# ipro6s register map
Vendor: intelpro; Series: IPRO6S
CPU: ipro6s, little endian
Registers are 32-bit, read-write, reset 0x0 unless marked. A register's access mark holds for its fields unless they carry their own. Offsets are from the block's base; [hi:lo] are bit positions; {n}, {i} and the like mark numbered series.

## MJENC_Q_SRAM
Base 0x3001A000
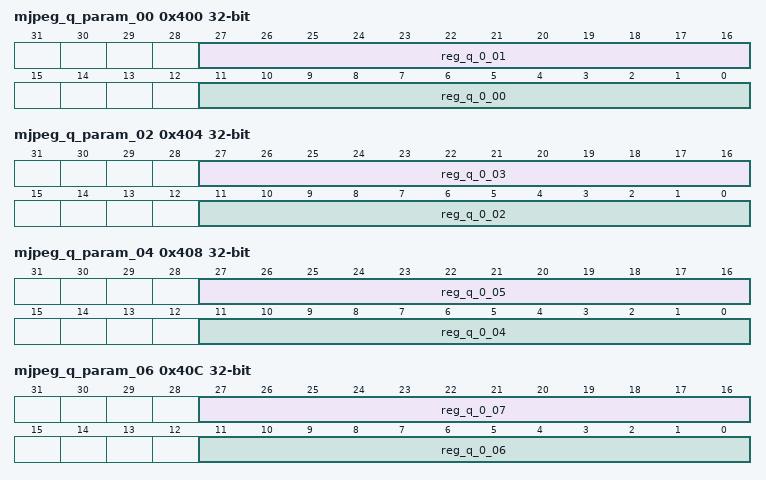
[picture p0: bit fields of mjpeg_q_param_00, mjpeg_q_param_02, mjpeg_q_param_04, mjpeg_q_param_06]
0x400 mjpeg_q_param_00
  [27:16] reg_q_0_01 — MJPEG Q parameter
  [11:0] reg_q_0_00 — MJPEG Q parameter
0x404 mjpeg_q_param_02
  [27:16] reg_q_0_03 — MJPEG Q parameter
  [11:0] reg_q_0_02 — MJPEG Q parameter
0x408 mjpeg_q_param_04
  [27:16] reg_q_0_05 — MJPEG Q parameter
  [11:0] reg_q_0_04 — MJPEG Q parameter
0x40C mjpeg_q_param_06
  [27:16] reg_q_0_07 — MJPEG Q parameter
  [11:0] reg_q_0_06 — MJPEG Q parameter
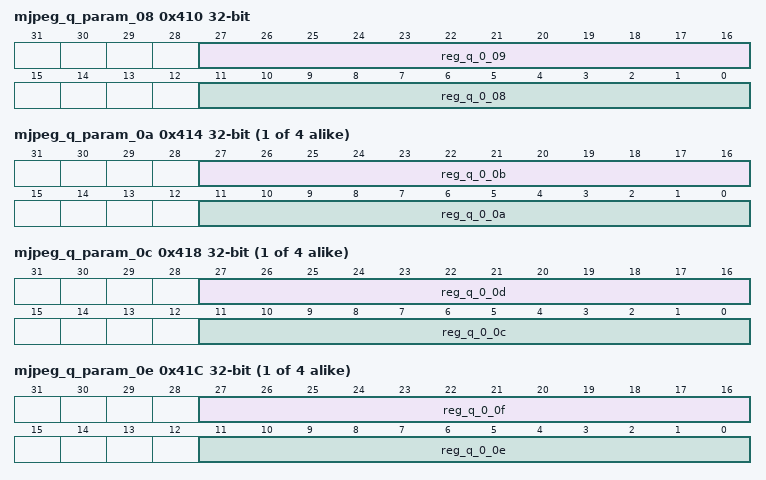
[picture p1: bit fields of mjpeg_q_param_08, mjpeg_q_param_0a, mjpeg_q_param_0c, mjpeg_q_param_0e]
0x410 mjpeg_q_param_08
  [27:16] reg_q_0_09 — MJPEG Q parameter
  [11:0] reg_q_0_08 — MJPEG Q parameter
{0x414+0x20*i} mjpeg_q_param_{i}a (i=0..3)
  [27:16] reg_q_0_{i}b — MJPEG Q parameter
  [11:0] reg_q_0_{i}a — MJPEG Q parameter
{0x418+0x20*i} mjpeg_q_param_{i}c (i=0..3)
  [27:16] reg_q_0_{i}d — MJPEG Q parameter
  [11:0] reg_q_0_{i}c — MJPEG Q parameter
{0x41C+0x20*i} mjpeg_q_param_{i}e (i=0..3)
  [27:16] reg_q_0_{i}f — MJPEG Q parameter
  [11:0] reg_q_0_{i}e — MJPEG Q parameter
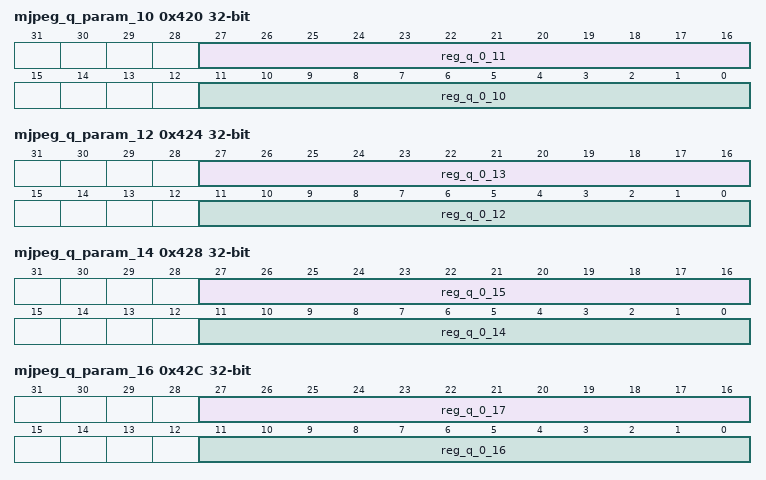
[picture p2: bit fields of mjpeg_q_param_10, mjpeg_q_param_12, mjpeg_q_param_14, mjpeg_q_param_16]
0x420 mjpeg_q_param_10
  [27:16] reg_q_0_11 — MJPEG Q parameter
  [11:0] reg_q_0_10 — MJPEG Q parameter
0x424 mjpeg_q_param_12
  [27:16] reg_q_0_13 — MJPEG Q parameter
  [11:0] reg_q_0_12 — MJPEG Q parameter
0x428 mjpeg_q_param_14
  [27:16] reg_q_0_15 — MJPEG Q parameter
  [11:0] reg_q_0_14 — MJPEG Q parameter
0x42C mjpeg_q_param_16
  [27:16] reg_q_0_17 — MJPEG Q parameter
  [11:0] reg_q_0_16 — MJPEG Q parameter
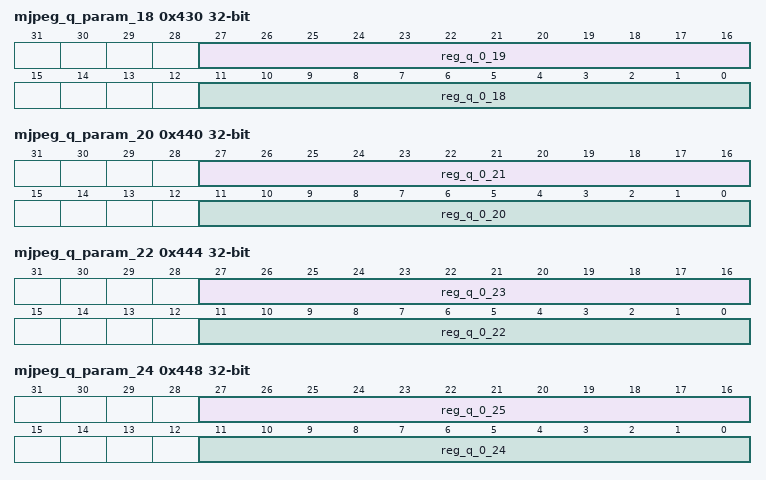
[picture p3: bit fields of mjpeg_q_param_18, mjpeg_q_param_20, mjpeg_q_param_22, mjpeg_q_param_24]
0x430 mjpeg_q_param_18
  [27:16] reg_q_0_19 — MJPEG Q parameter
  [11:0] reg_q_0_18 — MJPEG Q parameter
0x440 mjpeg_q_param_20
  [27:16] reg_q_0_21 — MJPEG Q parameter
  [11:0] reg_q_0_20 — MJPEG Q parameter
0x444 mjpeg_q_param_22
  [27:16] reg_q_0_23 — MJPEG Q parameter
  [11:0] reg_q_0_22 — MJPEG Q parameter
0x448 mjpeg_q_param_24
  [27:16] reg_q_0_25 — MJPEG Q parameter
  [11:0] reg_q_0_24 — MJPEG Q parameter
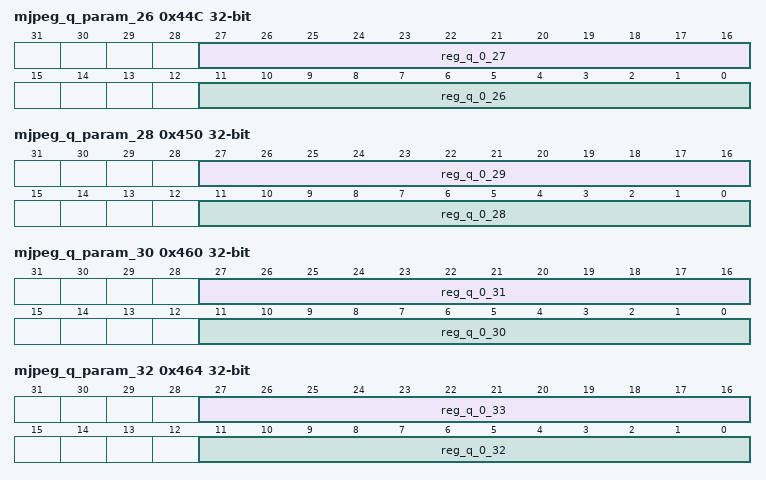
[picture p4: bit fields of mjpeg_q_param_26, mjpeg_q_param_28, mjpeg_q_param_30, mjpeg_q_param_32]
0x44C mjpeg_q_param_26
  [27:16] reg_q_0_27 — MJPEG Q parameter
  [11:0] reg_q_0_26 — MJPEG Q parameter
0x450 mjpeg_q_param_28
  [27:16] reg_q_0_29 — MJPEG Q parameter
  [11:0] reg_q_0_28 — MJPEG Q parameter
0x460 mjpeg_q_param_30
  [27:16] reg_q_0_31 — MJPEG Q parameter
  [11:0] reg_q_0_30 — MJPEG Q parameter
0x464 mjpeg_q_param_32
  [27:16] reg_q_0_33 — MJPEG Q parameter
  [11:0] reg_q_0_32 — MJPEG Q parameter
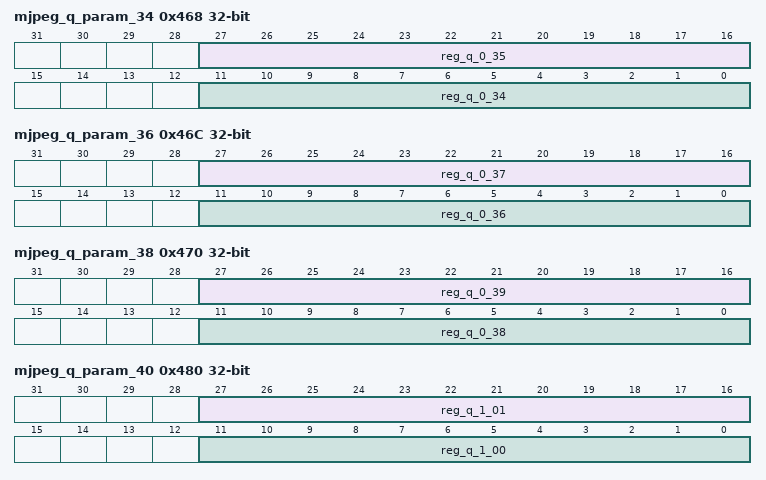
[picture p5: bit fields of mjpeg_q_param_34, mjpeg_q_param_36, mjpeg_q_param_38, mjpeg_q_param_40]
0x468 mjpeg_q_param_34
  [27:16] reg_q_0_35 — MJPEG Q parameter
  [11:0] reg_q_0_34 — MJPEG Q parameter
0x46C mjpeg_q_param_36
  [27:16] reg_q_0_37 — MJPEG Q parameter
  [11:0] reg_q_0_36 — MJPEG Q parameter
0x470 mjpeg_q_param_38
  [27:16] reg_q_0_39 — MJPEG Q parameter
  [11:0] reg_q_0_38 — MJPEG Q parameter
0x480 mjpeg_q_param_40
  [27:16] reg_q_1_01 — MJPEG Q parameter
  [11:0] reg_q_1_00 — MJPEG Q parameter
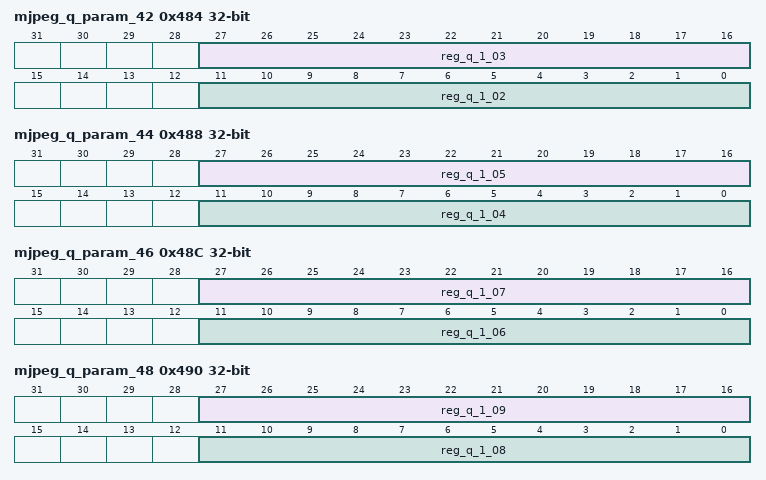
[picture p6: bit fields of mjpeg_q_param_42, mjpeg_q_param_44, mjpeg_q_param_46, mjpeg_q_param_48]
0x484 mjpeg_q_param_42
  [27:16] reg_q_1_03 — MJPEG Q parameter
  [11:0] reg_q_1_02 — MJPEG Q parameter
0x488 mjpeg_q_param_44
  [27:16] reg_q_1_05 — MJPEG Q parameter
  [11:0] reg_q_1_04 — MJPEG Q parameter
0x48C mjpeg_q_param_46
  [27:16] reg_q_1_07 — MJPEG Q parameter
  [11:0] reg_q_1_06 — MJPEG Q parameter
0x490 mjpeg_q_param_48
  [27:16] reg_q_1_09 — MJPEG Q parameter
  [11:0] reg_q_1_08 — MJPEG Q parameter
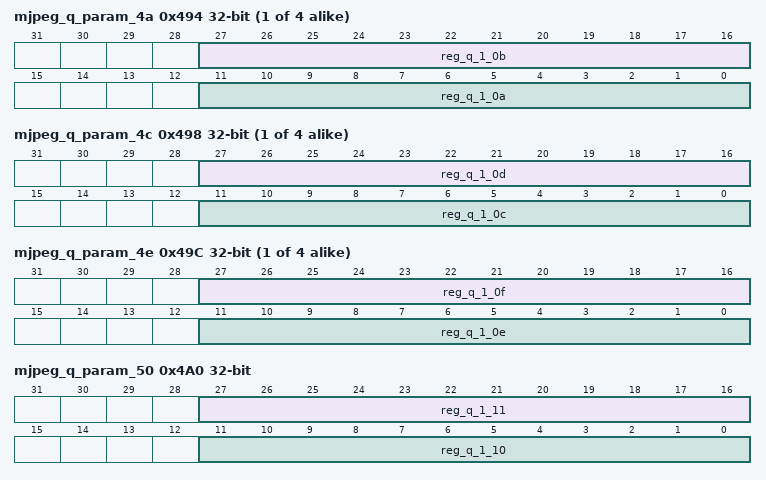
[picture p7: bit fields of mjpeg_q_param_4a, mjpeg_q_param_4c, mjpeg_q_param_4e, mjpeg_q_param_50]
{0x414+0x20*i} mjpeg_q_param_{i}a (i=4..7)
  [27:16] reg_q_1_{i-4}b — MJPEG Q parameter
  [11:0] reg_q_1_{i-4}a — MJPEG Q parameter
{0x418+0x20*i} mjpeg_q_param_{i}c (i=4..7)
  [27:16] reg_q_1_{i-4}d — MJPEG Q parameter
  [11:0] reg_q_1_{i-4}c — MJPEG Q parameter
{0x41C+0x20*i} mjpeg_q_param_{i}e (i=4..7)
  [27:16] reg_q_1_{i-4}f — MJPEG Q parameter
  [11:0] reg_q_1_{i-4}e — MJPEG Q parameter
0x4A0 mjpeg_q_param_50
  [27:16] reg_q_1_11 — MJPEG Q parameter
  [11:0] reg_q_1_10 — MJPEG Q parameter
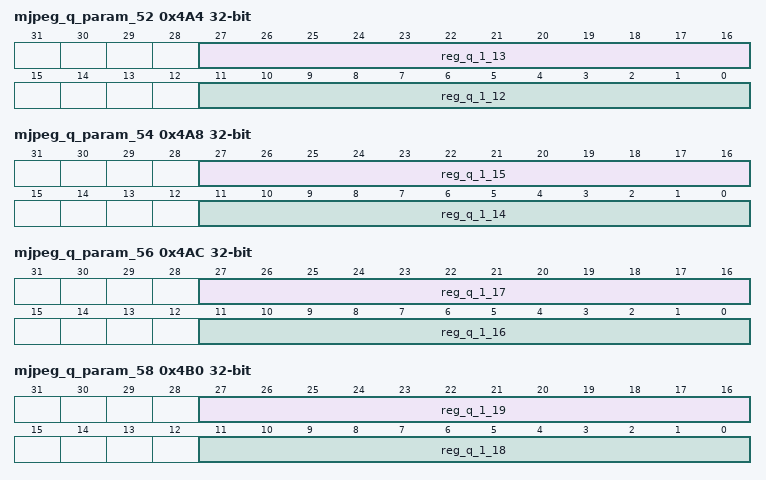
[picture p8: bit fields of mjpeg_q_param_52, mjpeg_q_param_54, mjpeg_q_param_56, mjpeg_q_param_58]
0x4A4 mjpeg_q_param_52
  [27:16] reg_q_1_13 — MJPEG Q parameter
  [11:0] reg_q_1_12 — MJPEG Q parameter
0x4A8 mjpeg_q_param_54
  [27:16] reg_q_1_15 — MJPEG Q parameter
  [11:0] reg_q_1_14 — MJPEG Q parameter
0x4AC mjpeg_q_param_56
  [27:16] reg_q_1_17 — MJPEG Q parameter
  [11:0] reg_q_1_16 — MJPEG Q parameter
0x4B0 mjpeg_q_param_58
  [27:16] reg_q_1_19 — MJPEG Q parameter
  [11:0] reg_q_1_18 — MJPEG Q parameter
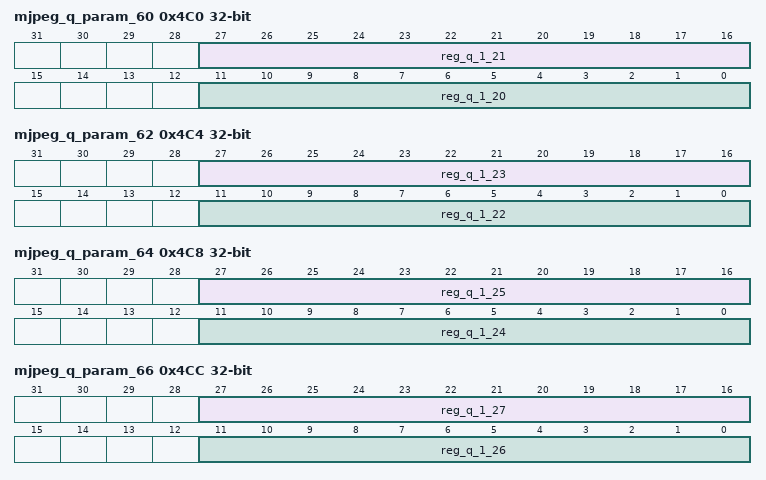
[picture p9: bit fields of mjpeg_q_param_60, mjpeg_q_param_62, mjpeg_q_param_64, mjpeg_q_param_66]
0x4C0 mjpeg_q_param_60
  [27:16] reg_q_1_21 — MJPEG Q parameter
  [11:0] reg_q_1_20 — MJPEG Q parameter
0x4C4 mjpeg_q_param_62
  [27:16] reg_q_1_23 — MJPEG Q parameter
  [11:0] reg_q_1_22 — MJPEG Q parameter
0x4C8 mjpeg_q_param_64
  [27:16] reg_q_1_25 — MJPEG Q parameter
  [11:0] reg_q_1_24 — MJPEG Q parameter
0x4CC mjpeg_q_param_66
  [27:16] reg_q_1_27 — MJPEG Q parameter
  [11:0] reg_q_1_26 — MJPEG Q parameter
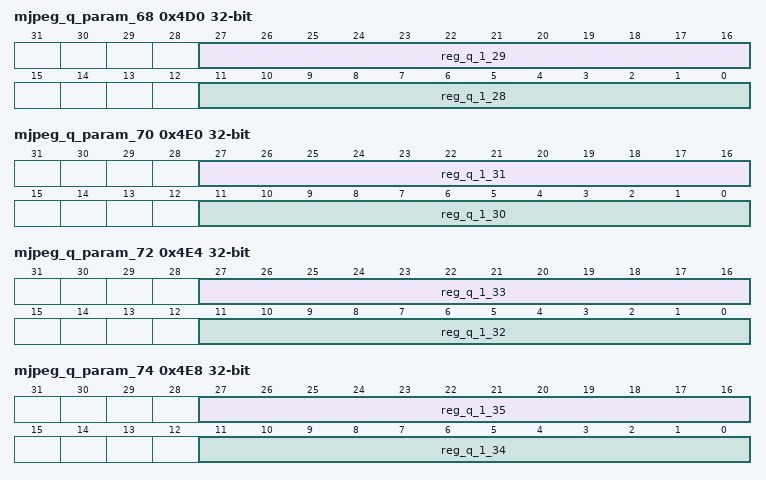
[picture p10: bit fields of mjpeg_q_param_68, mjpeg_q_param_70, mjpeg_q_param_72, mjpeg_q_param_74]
0x4D0 mjpeg_q_param_68
  [27:16] reg_q_1_29 — MJPEG Q parameter
  [11:0] reg_q_1_28 — MJPEG Q parameter
0x4E0 mjpeg_q_param_70
  [27:16] reg_q_1_31 — MJPEG Q parameter
  [11:0] reg_q_1_30 — MJPEG Q parameter
0x4E4 mjpeg_q_param_72
  [27:16] reg_q_1_33 — MJPEG Q parameter
  [11:0] reg_q_1_32 — MJPEG Q parameter
0x4E8 mjpeg_q_param_74
  [27:16] reg_q_1_35 — MJPEG Q parameter
  [11:0] reg_q_1_34 — MJPEG Q parameter
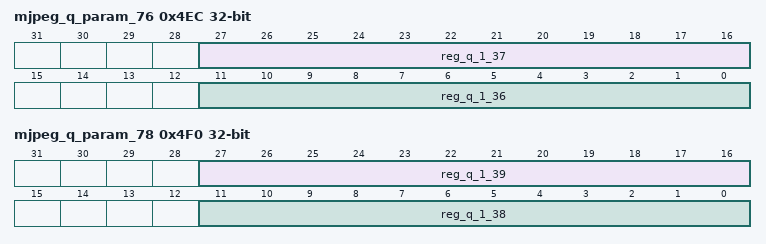
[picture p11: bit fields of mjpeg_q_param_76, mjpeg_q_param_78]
0x4EC mjpeg_q_param_76
  [27:16] reg_q_1_37 — MJPEG Q parameter
  [11:0] reg_q_1_36 — MJPEG Q parameter
0x4F0 mjpeg_q_param_78
  [27:16] reg_q_1_39 — MJPEG Q parameter
  [11:0] reg_q_1_38 — MJPEG Q parameter
